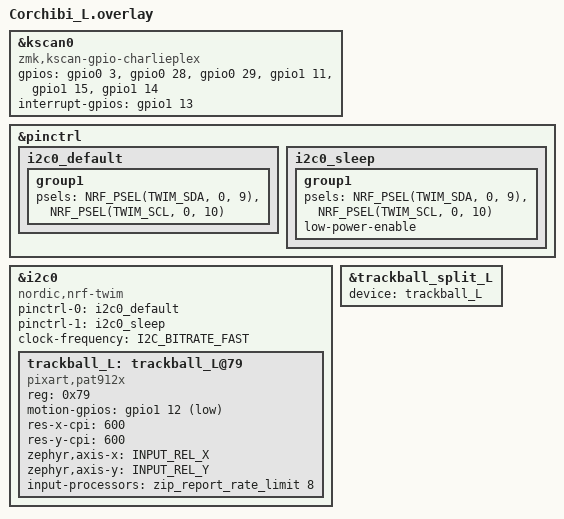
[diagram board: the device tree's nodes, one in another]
#include "corchibi.dtsi"
#include <dt-bindings/pinctrl/nrf-pinctrl.h>
#include <dt-bindings/zmk/input_transform.h>
#include <input/processors.dtsi>
#include <input/processors/report_rate_limit.dtsi>

&kscan0 {
    compatible = "zmk,kscan-gpio-charlieplex";
    gpios
        = <&gpio0 3 (GPIO_ACTIVE_HIGH)>
        , <&gpio0 28 (GPIO_ACTIVE_HIGH)>
        , <&gpio0 29 (GPIO_ACTIVE_HIGH)>
        , <&gpio1 11 (GPIO_ACTIVE_HIGH)>
        , <&gpio1 15 (GPIO_ACTIVE_HIGH)>
        , <&gpio1 14 (GPIO_ACTIVE_HIGH)>
        ;
    interrupt-gpios = <&gpio1 13 (GPIO_ACTIVE_HIGH | GPIO_PULL_DOWN)>;
};

&pinctrl {
    i2c0_default: i2c0_default {
        group1 {
            psels = <NRF_PSEL(TWIM_SDA, 0, 9)>,
                    <NRF_PSEL(TWIM_SCL, 0, 10)>;
        };
    };

    i2c0_sleep: i2c0_sleep {
        group1 {
            psels = <NRF_PSEL(TWIM_SDA, 0, 9)>,
                    <NRF_PSEL(TWIM_SCL, 0, 10)>;
            low-power-enable;
        };
    };
};

&i2c0 {
    status = "okay";
    compatible = "nordic,nrf-twim";
    pinctrl-0 = <&i2c0_default>;
    pinctrl-1 = <&i2c0_sleep>;
    pinctrl-names = "default", "sleep";
    clock-frequency = <I2C_BITRATE_FAST>;

    #address-cells = <1>;
    #size-cells = <0>;

    trackball_L: trackball_L@79 {
        compatible = "pixart,pat912x";
        reg = <0x79>;
        status = "okay";
        motion-gpios = <&gpio1 12 (GPIO_ACTIVE_LOW | GPIO_PULL_UP)>;
        res-x-cpi = <600>;
        res-y-cpi = <600>;
        zephyr,axis-x = <INPUT_REL_X>;
        zephyr,axis-y = <INPUT_REL_Y>;
        /* 左側はセンサー本体から通信を送る前に間引きます */
        input-processors = <&zip_report_rate_limit 8>;
    };
};

&trackball_split_L {
    device = <&trackball_L>;
};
